# R7FA0E303 register map
Vendor: Renesas Electronics Corporation; Series: RA0; File version: 1.00.00
CPU: CM23 r1p0, little endian, no MPU, no FPU, VTOR, 2 interrupt priority bits, 64 interrupts
Registers are 16-bit, read-write, reset 0x0 unless marked. A register's access mark holds for its fields unless they carry their own. Offsets are from the block's base; [hi:lo] are bit positions; {n}, {i} and the like mark numbered series; 'fields as' and 'values as' point back to an identical list.

## PFS_A — Pmn Pin Function Select
Base 0x400A0200
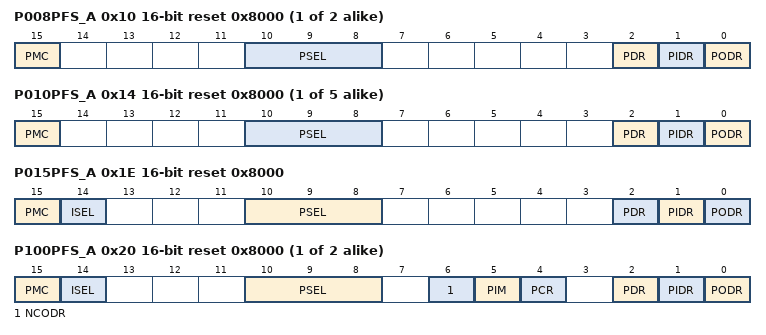
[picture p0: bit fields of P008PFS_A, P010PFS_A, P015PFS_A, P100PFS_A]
{0x0+2i} P00{i}PFS_A (i=8..9) reset 0x8000 — Port 00{i} Pin Function Select Register
  [15] PMC — Pin mode control
    0=Digital I/O; 1=Analog input function. Input to the input buffer is disabled
  [10:8] PSEL — Peripheral Select
  [2] PDR — Port Direction
    0=Input (functions as an input pin); 1=Output (functions as an output pin)
  [1] PIDR ro — Pmn State
    0=Low output; 1=High output
  [0] PODR — Port Output Data
    0=Low output; 1=High output
{0x0+2i} P0{i}PFS_A (i=10..14) reset 0x8000 — Port 0{i} Pin Function Select Register
  fields as P008PFS_A
0x1E P015PFS_A reset 0x8000 — Port 015 Pin Function Select Register
  [15] PMC — Pin mode control
    values as P008PFS_A.PMC
  [14] ISEL — IRQ Input Enable
    0=Not used as an IRQn input pin; 1=Used as an IRQn input pin
  [10:8] PSEL — Peripheral Select
  [2] PDR — Port Direction
    values as P008PFS_A.PDR
  [1] PIDR ro — Pmn State
    0=Low output; 1=High output
  [0] PODR — Port Output Data
    0=Low output; 1=High output
{0x20+2i} P10{i}PFS_A (i=0..1) reset 0x8000 — Port 10{i} Pin Function Select Register
  [15] PMC — Pin mode control
    values as P008PFS_A.PMC
  [14] ISEL — IRQ Input Enable
    0=Not used as an IRQn input pin; 1=Used as an IRQn input pin
  [10:8] PSEL — Peripheral Select
  [6] NCODR — N-channel Open-drain Control
    0=CMOS output; 1=NMOS open-drain output
  [5] PIM — Pin Input Buffer Selection
    0=Normal input buffer; 1=TTL input buffer
  [4] PCR — Pull-up Control
    0=Disable input pull-up; 1=Enable input pull-up
  [2] PDR — Port Direction
    values as P008PFS_A.PDR
  [1] PIDR ro — Pmn State
    0=Low output; 1=High output
  [0] PODR — Port Output Data
    0=Low output; 1=High output
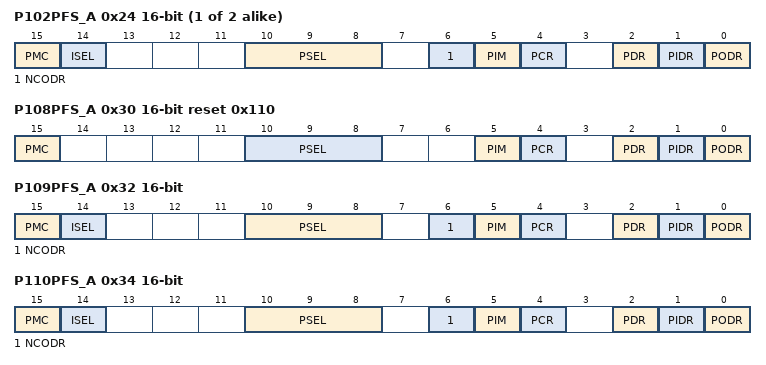
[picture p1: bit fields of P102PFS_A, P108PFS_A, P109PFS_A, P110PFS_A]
{0x20+2i} P10{i}PFS_A (i=2..3) (reset mask 0xFFFD) — Port 10{i} Pin Function Select Register
  fields as P100PFS_A
0x30 P108PFS_A reset 0x110 (reset mask 0xFFFD) — Port 108 Pin Function Select Register
  [15] PMC — Pin mode control
    values as P008PFS_A.PMC
  [10:8] PSEL — Peripheral Select
  [5] PIM — Pin Input Buffer Selection
    0=Normal input buffer; 1=TTL input buffer
  [4] PCR — Pull-up Control
    0=Disable input pull-up; 1=Enable input pull-up
  [2] PDR — Port Direction
    values as P008PFS_A.PDR
  [1] PIDR ro — Pmn State
    0=Low output; 1=High output
  [0] PODR — Port Output Data
    0=Low output; 1=High output
0x32 P109PFS_A (reset mask 0xFFFD) — Port 109 Pin Function Select Register
  fields as P100PFS_A
0x34 P110PFS_A (reset mask 0xFFFD) — Port 110 Pin Function Select Register
  fields as P100PFS_A
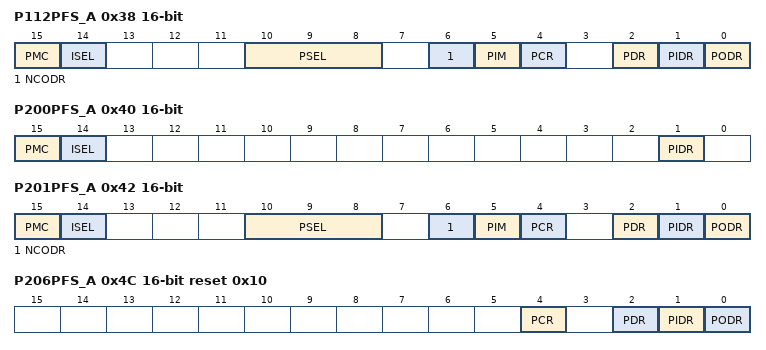
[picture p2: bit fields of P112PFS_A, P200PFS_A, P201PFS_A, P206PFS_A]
0x38 P112PFS_A (reset mask 0xFFFD) — Port 112 Pin Function Select Register
  fields as P100PFS_A
0x40 P200PFS_A (reset mask 0xFFFD) — Port 200 Pin Function Select Register
  [15] PMC — Pin mode control
    values as P008PFS_A.PMC
  [14] ISEL — IRQ Input Enable
    0=Not used as an IRQn input pin; 1=Used as an IRQn input pin
  [1] PIDR ro — Pmn State
    0=Low output; 1=High output
0x42 P201PFS_A (reset mask 0xFFFD) — Port 201 Pin Function Select Register
  [15] PMC — Pin mode control
    values as P008PFS_A.PMC
  [14] ISEL — IRQ Input Enable
    0=Not used as an IRQn input pin; 1=Used as an IRQn input pin
  [10:8] PSEL — Peripheral Select
  [6] NCODR — Port Direction
    values as P008PFS_A.PDR
  [5] PIM — Port Direction
    values as P008PFS_A.PDR
  [4] PCR — Pull-up Control
    0=Disable input pull-up; 1=Enable input pull-up
  [2] PDR — Port Direction
    values as P008PFS_A.PDR
  [1] PIDR ro — Pmn State
    0=Low output; 1=High output
  [0] PODR — Port Output Data
    0=Low output; 1=High output
0x4C P206PFS_A reset 0x10 (reset mask 0xFFFD) — Port 206 Pin Function Select Register
  [4] PCR — Pull-up Control
    0=Disable input pull-up; 1=Enable \input pull-up
  [2] PDR — Port Direction
    values as P008PFS_A.PDR
  [1] PIDR ro — Pmn State
    0=Low output; 1=High output
  [0] PODR — Port Output Data
    0=Low output; 1=High output
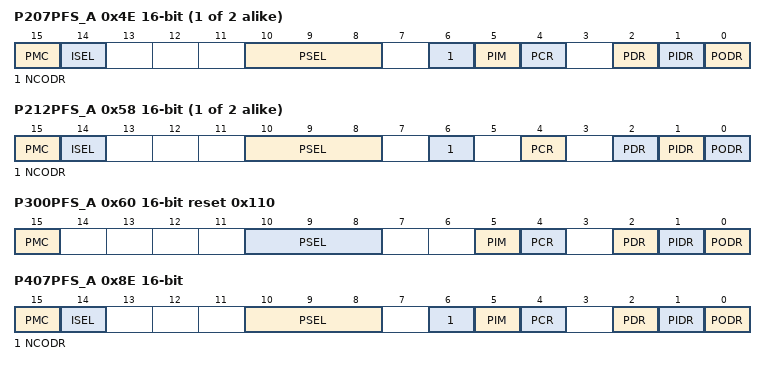
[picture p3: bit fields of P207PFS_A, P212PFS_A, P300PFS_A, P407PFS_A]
{0x40+2i} P20{i}PFS_A (i=7..8) (reset mask 0xFFFD) — Port 20{i} Pin Function Select Register
  fields as P201PFS_A
{0x40+2i} P2{i}PFS_A (i=12..13) (reset mask 0xFFFD) — Port 2{i} Pin Function Select Register
  [15] PMC — Pin mode control
    values as P008PFS_A.PMC
  [14] ISEL — IRQ Input Enable
    0=Not used as an IRQn input pin; 1=Used as an IRQn input pin
  [10:8] PSEL — Peripheral Select
  [6] NCODR — Port Direction
    values as P008PFS_A.PDR
  [4] PCR — Pull-up Control
    0=Disable input pull-up; 1=Enable input pull-up
  [2] PDR — Port Direction
    values as P008PFS_A.PDR
  [1] PIDR ro — Pmn State
    0=Low output; 1=High output
  [0] PODR — Port Output Data
    0=Low output; 1=High output
{0x40+2i} P2{i}PFS_A (i=14..15) (reset mask 0xFFFD) — Port 2{i} Pin Function Select Register
  [1] PIDR ro — Pmn State
    0=Low output; 1=High output
0x60 P300PFS_A reset 0x110 (reset mask 0xFFFD) — Port 300 Pin Function Select Register
  [15] PMC — Pin mode control
    values as P008PFS_A.PMC
  [10:8] PSEL — Peripheral Select
  [5] PIM — Port Direction
    values as P008PFS_A.PDR
  [4] PCR — Pull-up Control
    0=Disable input pull-up; 1=Enable input pull-up
  [2] PDR — Port Direction
    values as P008PFS_A.PDR
  [1] PIDR ro — Pmn State
    0=Low output; 1=High output
  [0] PODR — Port Output Data
    0=Low output; 1=High output
0x8E P407PFS_A (reset mask 0xFFFD) — Port 407 Pin Function Select Register
  fields as P201PFS_A
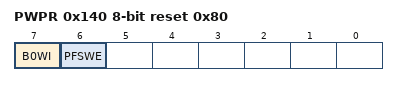
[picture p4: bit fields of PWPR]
0x140 PWPR 8-bit reset 0x80 — Write-Protect Register
  [7] B0WI — PFSWE Bit Write Disable
    0=Writing to the PFSWE bit is enabled; 1=Writing to the PFSWE bit is disabled
  [6] PFSWE — PmnPFS_A Register Write Enable
    0=Writing to the PmnPFS_A register is disabled; 1=Writing to the PmnPFS_A register is enabled
